# ADSP-2183xW_LPC register map
Vendor: Analog Devices; Series: ADSP-2183xW_LPC; File version: 3.0.3.517
CPU: 
Registers are 32-bit, read-write, reset 0x0 unless marked. A register's access mark holds for its fields unless they carry their own. Offsets are from the block's base; [hi:lo] are bit positions; {n}, {i} and the like mark numbered series.

## MISCREG — Misc registers for module are for integration purpose
Base 0x310A9000
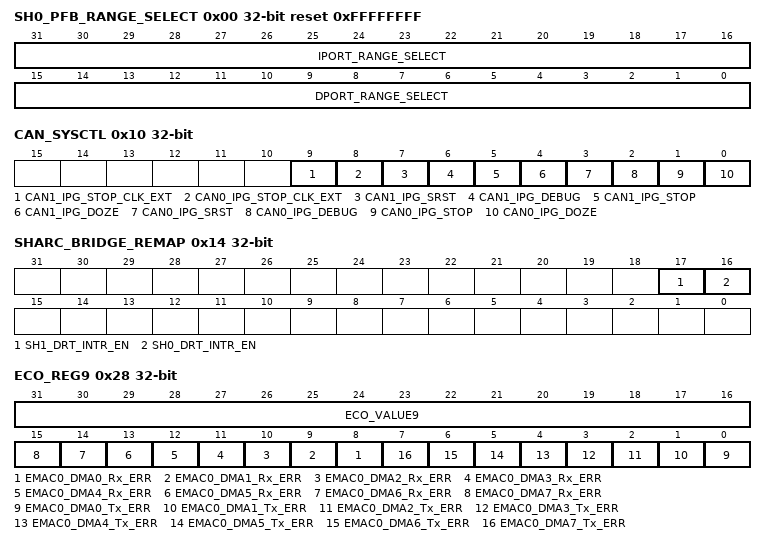
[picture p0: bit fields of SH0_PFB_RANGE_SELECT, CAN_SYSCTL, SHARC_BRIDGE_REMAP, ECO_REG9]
0x00 SH0_PFB_RANGE_SELECT reset 0xFFFFFFFF — SH0 Prefetch Range Selection Register
  [31:16] IPORT_RANGE_SELECT range 0x00000000..0x0000FFFF — IPORT Prefetch Range Select
  [15:0] DPORT_RANGE_SELECT range 0x00000000..0x0000FFFF — DPORT Prefetch Range Select
0x10 CAN_SYSCTL — CANFD Low Power Selection Mode
  [9] CAN1_IPG_STOP_CLK_EXT range 0x00000000..0x00000001 — CAN1 External Clock Gating Enable
  [8] CAN0_IPG_STOP_CLK_EXT range 0x00000000..0x00000001 — CAN0 External Clock Gating Enable
  [7] CAN1_IPG_SRST range 0x00000000..0x00000001 — CAN1 Soft Reset
  [6] CAN1_IPG_DEBUG range 0x00000000..0x00000001 — CAN1 Debug Mode
  [5] CAN1_IPG_STOP range 0x00000000..0x00000001 — CAN1 Stop Mode
  [4] CAN1_IPG_DOZE range 0x00000000..0x00000001 — CAN1 Doze Mode
  [3] CAN0_IPG_SRST range 0x00000000..0x00000001 — CAN0 Soft Reset
  [2] CAN0_IPG_DEBUG range 0x00000000..0x00000001 — CAN0 Debug Mode
  [1] CAN0_IPG_STOP range 0x00000000..0x00000001 — CAN0 Stop Mode
  [0] CAN0_IPG_DOZE range 0x00000000..0x00000001 — CAN0 Doze Mode
0x14 SHARC_BRIDGE_REMAP — SPORT Direct Interrupt Enable for SH0 and SH1
  [17] SH1_DRT_INTR_EN range 0x00000000..0x00000001 — SPORT Direct Interrupt Enable for SH1
  [16] SH0_DRT_INTR_EN range 0x00000000..0x00000001 — SPORT Direct Interrupt Enable for SH0
0x28 ECO_REG9 — Error Register
  [31:16] ECO_VALUE9 range 0x00000000..0x0000FFFF
  [n+8] EMAC0_DMA{n}_Rx_ERR rw-once range 0x00000000..0x00000001 (n=0..7) — DMA{n} Rx Error
  [n] EMAC0_DMA{n}_Tx_ERR rw-once range 0x00000000..0x00000001 (n=0..7) — DMA{n} Tx Error
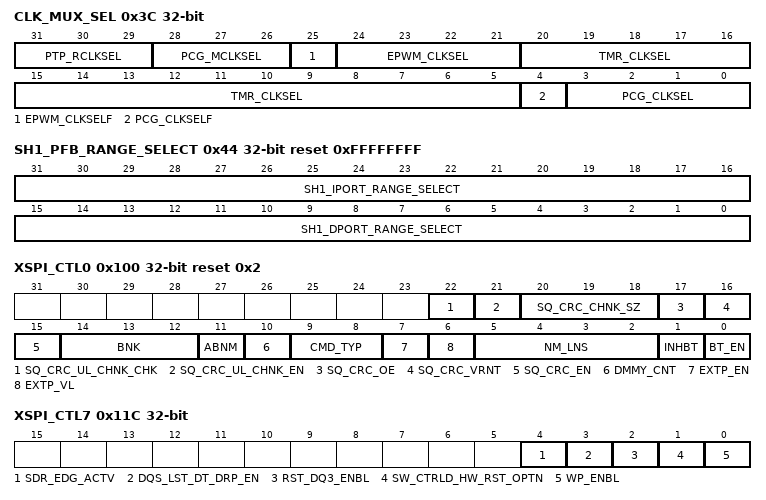
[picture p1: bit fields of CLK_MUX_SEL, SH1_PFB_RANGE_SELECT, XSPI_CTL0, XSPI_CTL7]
0x3C CLK_MUX_SEL — Misc Clock Mux Selection Register
  [31:29] PTP_RCLKSEL range 0x00000000..0x00000007 — PTP, GPIO Clock Selection for FPLL FIN
  [28:26] PCG_MCLKSEL range 0x00000000..0x00000007 — PCG Clock Selection for FPLL FIN
  [25] EPWM_CLKSELF — FPLL Clock Selection for PWM
  [24:21] EPWM_CLKSEL range 0x00000000..0x0000000F — PCG Clock Selection for PWM
  [20:5] TMR_CLKSEL range 0x00000000..0x0000FFFF — Individual Timer Clock Selection
  [4] PCG_CLKSELF — FPLL Clock Selection for Timer
  [3:0] PCG_CLKSEL range 0x00000000..0x0000000F — PCG Clock Selection for Timer
0x44 SH1_PFB_RANGE_SELECT reset 0xFFFFFFFF — SH1 Prefetch Range Selection Register
  [31:16] SH1_IPORT_RANGE_SELECT range 0x00000000..0x0000FFFF — SH1 IPORT Prefetch Range Select
  [15:0] SH1_DPORT_RANGE_SELECT range 0x00000000..0x0000FFFF — SH1 DPORT Prefetch Range Select
0x100 XSPI_CTL0 reset 0x2 — XSPI Boot/Init Control Register 0
  [22] SQ_CRC_UL_CHNK_CHK range 0x00000000..0x00000001 — Drives discovery_seq_crc_ual_chunk_chk port of xSPI controller.
  [21] SQ_CRC_UL_CHNK_EN range 0x00000000..0x00000001 — Drives discovery_seq_crc_ual_chunk_en port of xSPI controller.
  [20:18] SQ_CRC_CHNK_SZ range 0x00000000..0x00000007 — Drives discovery_seq_crc_chunk_size port of xSPI controller.
  [17] SQ_CRC_OE range 0x00000000..0x00000001 — Drives discovery_seq_crc_oe port of xSPI controller.
  [16] SQ_CRC_VRNT range 0x00000000..0x00000001 — Drives discovery_seq_crc_variant port of xSPI controller.
  [15] SQ_CRC_EN range 0x00000000..0x00000001 — Drives discovery_seq_crc_en port of xSPI controller.
  [14:12] BNK range 0x00000000..0x00000007 — Drives discovery_bank port of xSPI controller.
  [11] ABNM range 0x00000000..0x00000001 — Drives discovery_abnum port of xSPI controller.
  [10] DMMY_CNT range 0x00000000..0x00000001 — Drives discovery_dummy_cnt port of xSPI controller.
  [9:8] CMD_TYP range 0x00000000..0x00000003 — Drives discovery_cmd_type port of xSPI controller.
  [7] EXTP_EN range 0x00000000..0x00000001 — Drives discovery_extop_en port of xSPI controller.
  [6] EXTP_VL range 0x00000000..0x00000001 — Drives discovery_extop_val port of xSPI controller.
  [5:2] NM_LNS range 0x00000000..0x0000000F — Drives discovery_num_lines port of xSPI controller.
  [1] INHBT range 0x00000000..0x00000001 — Drives discovery_inhibit port of xSPI controller.
  [0] BT_EN range 0x00000000..0x00000001 — Samples boot_en port of xSPI PHY
0x104 XSPI_CTL1 — XSPI Boot/Init Control Register 1
  [31:0] RB_VLD_TM range 0x00000000..0xFFFFFFFF — Drives init_rb_valid_time port of xSPI controller.
0x108 XSPI_CTL2 reset 0x80000101 — XSPI Boot/Init Control Register 2
  [31:0] PHY_DQ_TMNG range 0x00000000..0xFFFFFFFF — Drives init_phy_dq_timing_reg port of xSPI controller.
0x10C XSPI_CTL3 reset 0x300404 — XSPI Boot/Init Control Register 3
  [31:0] PHY_DQS_TMNG range 0x00000000..0xFFFFFFFF — Drives init_phy_dqs_timing_reg port of xSPI controller.
0x110 XSPI_CTL4 reset 0x180030 — XSPI Boot/Init Control Register 4
  [31:0] PHY_GT_LPBK_CTRL range 0x00000000..0xFFFFFFFF — Drives init_phy_gate_lpbk_ctrl_reg port of xSPI controller.
0x114 XSPI_CTL5 reset 0x800004 — XSPI Boot/Init Control Register 5
  [31:0] PHY_DLL_MSTR_CTRL range 0x00000000..0xFFFFFFFF — Drives init_phy_dll_master_ctrl_reg port of xSPI controller.
0x118 XSPI_CTL6 reset 0x357F — XSPI Boot/Init Control Register 6
  [31:0] PHY_DLL_SLV_CTRL range 0x00000000..0xFFFFFFFF — Drives init_phy_dll_slave_ctrl_reg port of xSPI controller.
0x11C XSPI_CTL7 — XSPI Boot/Init Control Register 7
  [4] SDR_EDG_ACTV range 0x00000000..0x00000001 — Drives init_sdr_edge_active port of xSPI controller.
  [3] DQS_LST_DT_DRP_EN range 0x00000000..0x00000001 — Drives init_dqs_last_data_drop_en port of xSPI controller.
  [2] RST_DQ3_ENBL range 0x00000000..0x00000001 — Drives init_rst_dq3_enable port of xSPI controller.
  [1] SW_CTRLD_HW_RST_OPTN range 0x00000000..0x00000001 — Drives init_sw_ctrled_hw_rst_option port of xSPI controller.
  [0] WP_ENBL range 0x00000000..0x00000001 — Drives init_wp_enable port of xSPI controller.
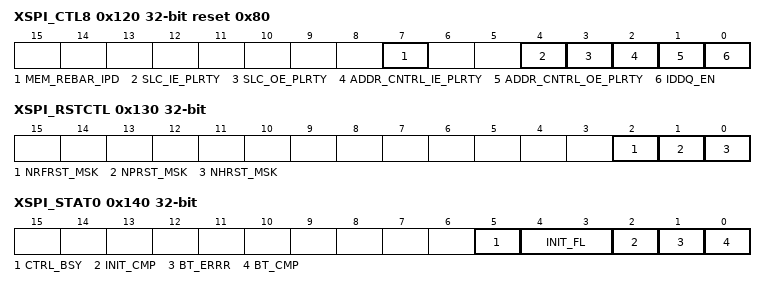
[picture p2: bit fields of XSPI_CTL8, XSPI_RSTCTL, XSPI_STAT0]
0x120 XSPI_CTL8 reset 0x80 — XSPI Boot/Init Control Register 7
  [7] MEM_REBAR_IPD range 0x00000000..0x00000001 — Drives mem_rebar_ipad port of xSPI PHY
  [4] SLC_IE_PLRTY range 0x00000000..0x00000001 — Drives slice_ie_polarity port of xSPI PHY
  [3] SLC_OE_PLRTY range 0x00000000..0x00000001 — Drives slice_oe_polarity port of xSPI PHY
  [2] ADDR_CNTRL_IE_PLRTY range 0x00000000..0x00000001 — Drives addr_cntrl_ie_polarity port of xSPI PHY
  [1] ADDR_CNTRL_OE_PLRTY range 0x00000000..0x00000001 — Drives addr_cntrl_oe_polarity port of xSPI PHY
  [0] IDDQ_EN range 0x00000000..0x00000001 — Drives iddq_en port of xSPI PHY
0x130 XSPI_RSTCTL — XSPI Boot/Init Reset Control Register
  [2] NRFRST_MSK range 0x00000000..0x00000001 — xSPI Controller and PHY xSPI Domain Reset Mask
  [1] NPRST_MSK range 0x00000000..0x00000001 — xSPI Controller and PHY MMR Reset Mask
  [0] NHRST_MSK range 0x00000000..0x00000001 — xSPI Controller System Reset Mask
0x140 XSPI_STAT0 — XSPI Boot/Init Status Register
  [5] CTRL_BSY range 0x00000000..0x00000001 — Samples ctrl_busy port of xSPI controller.
  [4:3] INIT_FL range 0x00000000..0x00000003 — Samples init_fail port of xSPI controller.
  [2] INIT_CMP range 0x00000000..0x00000001 — Samples init_comp port of xSPI controller.
  [1] BT_ERRR range 0x00000000..0x00000001 — Samples boot_error port of xSPI controller.
  [0] BT_CMP range 0x00000000..0x00000001 — Samples boot_comp port of xSPI controller.
